# CY8C5868AXI_LP035 register map
File version: 0.1
Registers are 8-bit, read-write, no defined reset value unless marked. A register's access mark holds for its fields unless they carry their own. Offsets are from the block's base; [hi:lo] are bit positions; 'fields as' and 'values as' point back to an identical list.

## SR2
Base 0x00000000
0x40006468 SR2_STATUS_REG
0x40006488 SR2_MASK_REG
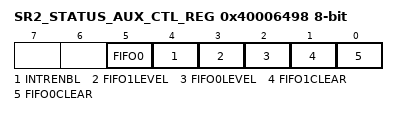
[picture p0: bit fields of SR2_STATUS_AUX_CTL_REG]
0x40006498 SR2_STATUS_AUX_CTL_REG
  [5] FIFO0 — FIFO0 clear
    1=ENABLED (Enable counter); 0=DISABLED (Disable counter)
  [4] INTRENBL — Enables or disables the Interrupt
    1=ENABLED (Interrupt enabled); 0=DISABLED (Interrupt disabled)
  [3] FIFO1LEVEL — FIFO level
    1=ENABLED (FIFO LVL: input mode: FIFO at least 1/2 empty; output mode: FIFO at least 1/2 full); 0=DISABLED (FIFO LVL: input mode: FIFO not full; output mode: FIFO not empty)
  [2] FIFO0LEVEL — FIFO level
    values as FIFO1LEVEL
  [1] FIFO1CLEAR — FIFO clear
    1=ENABLED (Clear FIFO state); 0=DISABLED (Normal FIFO operation)
  [0] FIFO0CLEAR — FIFO clear
    values as FIFO1CLEAR

## PWM1y
Base 0x00000000
0x4000652B PWM1y_COMPARE_Reg_ — UDB.D0 - Assigned Compare Value
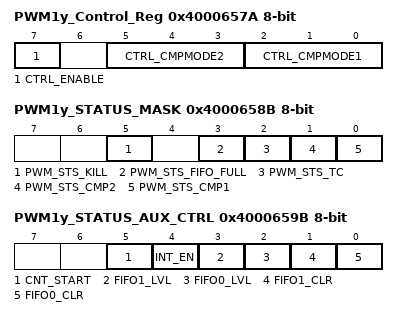
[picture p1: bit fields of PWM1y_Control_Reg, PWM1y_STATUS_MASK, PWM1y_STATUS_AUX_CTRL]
0x4000657A PWM1y_Control_Reg — UDB Control Register - Assigned Control Register Value
  [7] CTRL_ENABLE — Enable the PWM
  [5:3] CTRL_CMPMODE2 — Compare mode 2
  [2:0] CTRL_CMPMODE1 — Compare mode 1
0x4000658B PWM1y_STATUS_MASK — UDB Status bits Interrupt Mask Enable Register
  [5] PWM_STS_KILL ro — Enables the Interrupt on Kill
  [3] PWM_STS_FIFO_FULL ro — FIFO Full Status Mask
  [2] PWM_STS_TC ro — Enables the Interrupt on Terminal Count
  [1] PWM_STS_CMP2 ro — Enables the Interrupt on Compare 2
  [0] PWM_STS_CMP1 ro — Enables the Interrupt on Compare 1
0x4000659B PWM1y_STATUS_AUX_CTRL — UDB Auxilliary Control Register
  [5] CNT_START — FIFO0 clear
    0=E_CNT_START0 (Disable counter); 1=E_CNT_START1 (Enable counter)
  [4] INT_EN
    0=E_INT_EN0 (Interrupt disabled); 1=E_INT_EN1 (Interrupt enabled)
  [3] FIFO1_LVL — FIFO level
    0=E_FIFO_LVL_0 (FIFO LVL: input mode: FIFO not full; output mode: FIFO not empty); 1=E_FIFO_LVL_1 (FIFO LVL: input mode: FIFO at least 1/2 empty; output mode: FIFO at least 1/2 full)
  [2] FIFO0_LVL — FIFO level
    values as FIFO1_LVL
  [1] FIFO1_CLR — FIFO1 clear
    0=E_FIFO_CLR_0 (Normal FIFO operation); 1=E_FIFO_CLR_1 (Clear FIFO state)
  [0] FIFO0_CLR — FIFO0 clear
    values as FIFO1_CLR

## PWM2y
Base 0x00000000
0x4000652A PWM2y_COMPARE_Reg_ — UDB.D0 - Assigned Compare Value
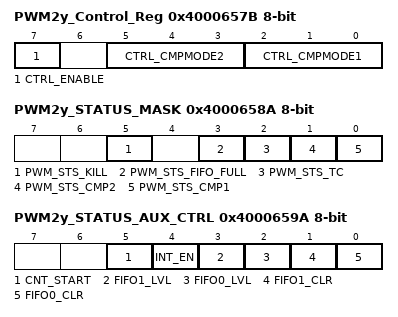
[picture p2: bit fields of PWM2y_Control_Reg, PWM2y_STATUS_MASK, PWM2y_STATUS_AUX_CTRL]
0x4000657B PWM2y_Control_Reg — UDB Control Register - Assigned Control Register Value
  [7] CTRL_ENABLE — Enable the PWM
  [5:3] CTRL_CMPMODE2 — Compare mode 2
  [2:0] CTRL_CMPMODE1 — Compare mode 1
0x4000658A PWM2y_STATUS_MASK — UDB Status bits Interrupt Mask Enable Register
  [5] PWM_STS_KILL ro — Enables the Interrupt on Kill
  [3] PWM_STS_FIFO_FULL ro — FIFO Full Status Mask
  [2] PWM_STS_TC ro — Enables the Interrupt on Terminal Count
  [1] PWM_STS_CMP2 ro — Enables the Interrupt on Compare 2
  [0] PWM_STS_CMP1 ro — Enables the Interrupt on Compare 1
0x4000659A PWM2y_STATUS_AUX_CTRL — UDB Auxilliary Control Register
  [5] CNT_START — FIFO0 clear
    0=E_CNT_START0 (Disable counter); 1=E_CNT_START1 (Enable counter)
  [4] INT_EN
    0=E_INT_EN0 (Interrupt disabled); 1=E_INT_EN1 (Interrupt enabled)
  [3] FIFO1_LVL — FIFO level
    0=E_FIFO_LVL_0 (FIFO LVL: input mode: FIFO not full; output mode: FIFO not empty); 1=E_FIFO_LVL_1 (FIFO LVL: input mode: FIFO at least 1/2 empty; output mode: FIFO at least 1/2 full)
  [2] FIFO0_LVL — FIFO level
    values as FIFO1_LVL
  [1] FIFO1_CLR — FIFO1 clear
    0=E_FIFO_CLR_0 (Normal FIFO operation); 1=E_FIFO_CLR_1 (Clear FIFO state)
  [0] FIFO0_CLR — FIFO0 clear
    values as FIFO1_CLR

## PWM2p
Base 0x00000000
0x40006429 PWM2p_COMPARE_Reg_ — UDB.D0 - Assigned Compare Value
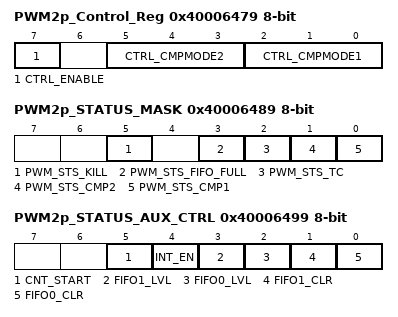
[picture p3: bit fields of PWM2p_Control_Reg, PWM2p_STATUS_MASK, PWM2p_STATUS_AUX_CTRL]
0x40006479 PWM2p_Control_Reg — UDB Control Register - Assigned Control Register Value
  [7] CTRL_ENABLE — Enable the PWM
  [5:3] CTRL_CMPMODE2 — Compare mode 2
  [2:0] CTRL_CMPMODE1 — Compare mode 1
0x40006489 PWM2p_STATUS_MASK — UDB Status bits Interrupt Mask Enable Register
  [5] PWM_STS_KILL ro — Enables the Interrupt on Kill
  [3] PWM_STS_FIFO_FULL ro — FIFO Full Status Mask
  [2] PWM_STS_TC ro — Enables the Interrupt on Terminal Count
  [1] PWM_STS_CMP2 ro — Enables the Interrupt on Compare 2
  [0] PWM_STS_CMP1 ro — Enables the Interrupt on Compare 1
0x40006499 PWM2p_STATUS_AUX_CTRL — UDB Auxilliary Control Register
  [5] CNT_START — FIFO0 clear
    0=E_CNT_START0 (Disable counter); 1=E_CNT_START1 (Enable counter)
  [4] INT_EN
    0=E_INT_EN0 (Interrupt disabled); 1=E_INT_EN1 (Interrupt enabled)
  [3] FIFO1_LVL — FIFO level
    0=E_FIFO_LVL_0 (FIFO LVL: input mode: FIFO not full; output mode: FIFO not empty); 1=E_FIFO_LVL_1 (FIFO LVL: input mode: FIFO at least 1/2 empty; output mode: FIFO at least 1/2 full)
  [2] FIFO0_LVL — FIFO level
    values as FIFO1_LVL
  [1] FIFO1_CLR — FIFO1 clear
    0=E_FIFO_CLR_0 (Normal FIFO operation); 1=E_FIFO_CLR_1 (Clear FIFO state)
  [0] FIFO0_CLR — FIFO0 clear
    values as FIFO1_CLR

## PWM1p
Base 0x00000000
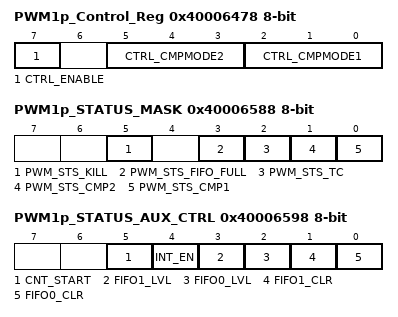
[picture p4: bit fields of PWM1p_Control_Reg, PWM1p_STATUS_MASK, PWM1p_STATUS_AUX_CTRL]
0x40006478 PWM1p_Control_Reg — UDB Control Register - Assigned Control Register Value
  [7] CTRL_ENABLE — Enable the PWM
  [5:3] CTRL_CMPMODE2 — Compare mode 2
  [2:0] CTRL_CMPMODE1 — Compare mode 1
0x40006528 PWM1p_COMPARE_Reg_ — UDB.D0 - Assigned Compare Value
0x40006588 PWM1p_STATUS_MASK — UDB Status bits Interrupt Mask Enable Register
  [5] PWM_STS_KILL ro — Enables the Interrupt on Kill
  [3] PWM_STS_FIFO_FULL ro — FIFO Full Status Mask
  [2] PWM_STS_TC ro — Enables the Interrupt on Terminal Count
  [1] PWM_STS_CMP2 ro — Enables the Interrupt on Compare 2
  [0] PWM_STS_CMP1 ro — Enables the Interrupt on Compare 1
0x40006598 PWM1p_STATUS_AUX_CTRL — UDB Auxilliary Control Register
  [5] CNT_START — FIFO0 clear
    0=E_CNT_START0 (Disable counter); 1=E_CNT_START1 (Enable counter)
  [4] INT_EN
    0=E_INT_EN0 (Interrupt disabled); 1=E_INT_EN1 (Interrupt enabled)
  [3] FIFO1_LVL — FIFO level
    0=E_FIFO_LVL_0 (FIFO LVL: input mode: FIFO not full; output mode: FIFO not empty); 1=E_FIFO_LVL_1 (FIFO LVL: input mode: FIFO at least 1/2 empty; output mode: FIFO at least 1/2 full)
  [2] FIFO0_LVL — FIFO level
    values as FIFO1_LVL
  [1] FIFO1_CLR — FIFO1 clear
    0=E_FIFO_CLR_0 (Normal FIFO operation); 1=E_FIFO_CLR_1 (Clear FIFO state)
  [0] FIFO0_CLR — FIFO0 clear
    values as FIFO1_CLR
